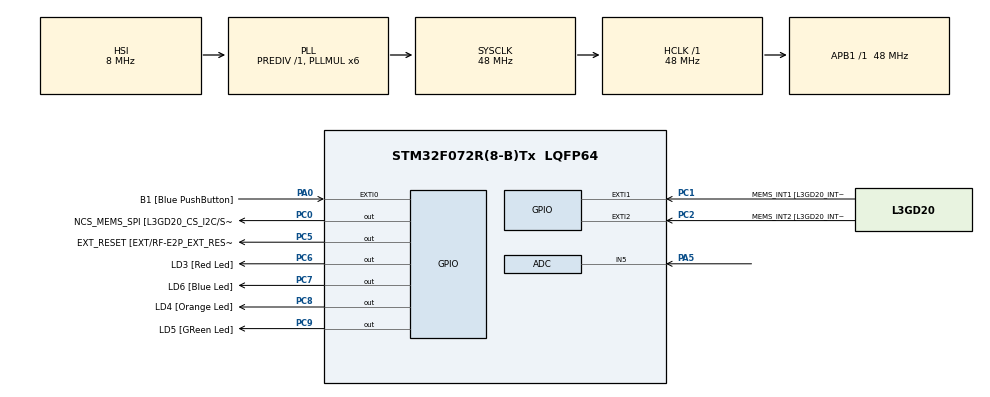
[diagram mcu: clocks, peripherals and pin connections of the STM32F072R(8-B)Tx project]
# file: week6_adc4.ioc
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ADC.ContinuousConvMode=ENABLE
ADC.SamplingTime=ADC_SAMPLETIME_55CYCLES_5
Mcu.Family=STM32F0
Mcu.Name=STM32F072R(8-B)Tx
Mcu.Package=LQFP64
NVIC.ADC1_COMP_IRQn=true\:0\:0\:false\:false\:true\:true\:true\:true
PA0.GPIO_Label=B1 [Blue PushButton]
PA0.GPIO_ModeDefaultEXTI=GPIO_MODE_EVT_RISING
PA0.Signal=GPXTI0
PA11.GPIO_Label=USBF4_DM
PA11.Signal=USB_DM
PA12.GPIO_Label=USBF4_DP
PA12.Signal=USB_DP
PA13.GPIO_Label=SWDIO
PA13.Mode=Serial_Wire
PA13.Signal=SYS_SWDIO
PA14.GPIO_Label=SWCLK
PA14.Mode=Serial_Wire
PA14.Signal=SYS_SWCLK
PA2.Signal=TSC_G1_IO3
PA3.Signal=TSC_G1_IO4
PA5.Mode=IN5
PA5.Signal=ADC_IN5
PA6.Signal=TSC_G2_IO3
PA7.Signal=TSC_G2_IO4
PB0.Signal=TSC_G3_IO2
PB1.Signal=TSC_G3_IO3
PB10.GPIO_Label=I2C2_SCL[EXT/RF-E2P_SCL]
PB10.Signal=I2C2_SCL
PB11.GPIO_Label=I2C2_SDA[EXT/RF-E2P_SDA]
PB11.Signal=I2C2_SDA
PB13.GPIO_Label=SPI2_SCK [L3GD20_SCL/SPC]
PB13.Signal=SPI2_SCK
PB14.GPIO_Label=SPI2_MISO [L3GD20_SDO]
PB14.Signal=SPI2_MISO
PB15.GPIO_Label=SPI2_MOSI [L3GD20_SDA/SDI]
PB15.Signal=SPI2_MOSI
PC0.GPIO_Label=NCS_MEMS_SPI [L3GD20_CS_I2C/SPI]
PC0.Signal=GPIO_Output
PC1.GPIO_Label=MEMS_INT1 [L3GD20_INT1]
PC1.GPIO_ModeDefaultEXTI=GPIO_MODE_EVT_RISING
PC1.Signal=GPXTI1
PC2.GPIO_Label=MEMS_INT2 [L3GD20_INT2]
PC2.GPIO_ModeDefaultEXTI=GPIO_MODE_EVT_RISING
PC2.Signal=GPXTI2
PC5.GPIO_Label=EXT_RESET [EXT/RF-E2P_EXT_RESET]
PC5.Signal=GPIO_Output
PC6.GPIO_Label=LD3 [Red Led]
PC6.Signal=GPIO_Output
PC7.GPIO_Label=LD6 [Blue Led]
PC7.Signal=GPIO_Output
PC8.GPIO_Label=LD4 [Orange Led]
PC8.Signal=GPIO_Output
PC9.GPIO_Label=LD5 [GReen Led]
PC9.Signal=GPIO_Output
ProjectManager.HeapSize=0x200
ProjectManager.StackSize=0x400
ProjectManager.TargetToolchain=STM32CubeIDE
RCC.AHBFreq_Value=48000000
RCC.APB1Freq_Value=48000000
RCC.APB1TimFreq_Value=48000000
RCC.HCLKFreq_Value=48000000
RCC.PLLMUL=RCC_PLL_MUL6
RCC.SYSCLKFreq_VALUE=48000000
RCC.SYSCLKSource=RCC_SYSCLKSOURCE_PLLCLK
board=STM32F072B-DISCO

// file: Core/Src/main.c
/* USER CODE BEGIN Header */
/**
  ******************************************************************************
  * @file           : main.c
  * @brief          : Main program body
  ******************************************************************************
  * @attention
  *
  * Copyright (c) 2024 STMicroelectronics.
  * All rights reserved.
  *
  * This software is licensed under terms that can be found in the LICENSE file
  * in the root directory of this software component.
  * If no LICENSE file comes with this software, it is provided AS-IS.
  *
  ******************************************************************************
  */
/* USER CODE END Header */
#include "main.h"

ADC_HandleTypeDef hadc;
uint16_t adcvalue=0;

void SystemClock_Config(void);
static void MX_GPIO_Init(void);
static void MX_ADC_Init(void);

int main(void)
{

  /* MCU Configuration--------------------------------------------------------*/

  /* Reset of all peripherals, Initializes the Flash interface and the Systick. */
  HAL_Init();

  /* Configure the system clock */
  SystemClock_Config();

  /* Initialize all configured peripherals */
  MX_GPIO_Init();
  MX_ADC_Init();
  /* USER CODE BEGIN 2 */
// Optionally, in case of usage of ADC with interruptions:
//         (++) Configure the NVIC for ADC
//              using function HAL_NVIC_EnableIRQ(ADCx_IRQn)
//         (++) Insert the ADC interruption handler function HAL_ADC_IRQHandler()
//              into the function of corresponding ADC interruption vector
//              ADCx_IRQHandler().
  /* USER CODE END 2 */
HAL_ADC_Start_IT(&hadc);

  /* Infinite loop */
  while (1)
  {

  }
}

void SystemClock_Config(void)
{
  RCC_OscInitTypeDef RCC_OscInitStruct = {0};
  RCC_ClkInitTypeDef RCC_ClkInitStruct = {0};

  /** Initializes the RCC Oscillators according to the specified parameters
  * in the RCC_OscInitTypeDef structure.
  */
  RCC_OscInitStruct.OscillatorType = RCC_OSCILLATORTYPE_HSI|RCC_OSCILLATORTYPE_HSI14;
  RCC_OscInitStruct.HSIState = RCC_HSI_ON;
  RCC_OscInitStruct.HSI14State = RCC_HSI14_ON;
  RCC_OscInitStruct.HSICalibrationValue = RCC_HSICALIBRATION_DEFAULT;
  RCC_OscInitStruct.HSI14CalibrationValue = 16;
  RCC_OscInitStruct.PLL.PLLState = RCC_PLL_ON;
  RCC_OscInitStruct.PLL.PLLSource = RCC_PLLSOURCE_HSI;
  RCC_OscInitStruct.PLL.PLLMUL = RCC_PLL_MUL6;
  RCC_OscInitStruct.PLL.PREDIV = RCC_PREDIV_DIV1;
  if (HAL_RCC_OscConfig(&RCC_OscInitStruct) != HAL_OK)
  {
    Error_Handler();
  }

  /** Initializes the CPU, AHB and APB buses clocks
  */
  RCC_ClkInitStruct.ClockType = RCC_CLOCKTYPE_HCLK|RCC_CLOCKTYPE_SYSCLK
                              |RCC_CLOCKTYPE_PCLK1;
  RCC_ClkInitStruct.SYSCLKSource = RCC_SYSCLKSOURCE_PLLCLK;
  RCC_ClkInitStruct.AHBCLKDivider = RCC_SYSCLK_DIV1;
  RCC_ClkInitStruct.APB1CLKDivider = RCC_HCLK_DIV1;

  if (HAL_RCC_ClockConfig(&RCC_ClkInitStruct, FLASH_LATENCY_1) != HAL_OK)
  {
    Error_Handler();
  }
}

static void MX_ADC_Init(void)
{

  ADC_ChannelConfTypeDef sConfig = {0};

  /** Configure the global features of the ADC (Clock, Resolution, Data Alignment and number of conversion)
  */
  hadc.Instance = ADC1;
  hadc.Init.ClockPrescaler = ADC_CLOCK_ASYNC_DIV1;
  hadc.Init.Resolution = ADC_RESOLUTION_12B;
  hadc.Init.DataAlign = ADC_DATAALIGN_RIGHT;
  hadc.Init.ScanConvMode = ADC_SCAN_DIRECTION_FORWARD;
  hadc.Init.EOCSelection = ADC_EOC_SINGLE_CONV;
  hadc.Init.LowPowerAutoWait = DISABLE;
  hadc.Init.LowPowerAutoPowerOff = DISABLE;
  hadc.Init.ContinuousConvMode = ENABLE;
  hadc.Init.DiscontinuousConvMode = DISABLE;
  hadc.Init.ExternalTrigConv = ADC_SOFTWARE_START;
  hadc.Init.ExternalTrigConvEdge = ADC_EXTERNALTRIGCONVEDGE_NONE;
  hadc.Init.DMAContinuousRequests = DISABLE;
  hadc.Init.Overrun = ADC_OVR_DATA_PRESERVED;
  if (HAL_ADC_Init(&hadc) != HAL_OK)
  {
    Error_Handler();
  }

  /** Configure for the selected ADC regular channel to be converted.
  */
  sConfig.Channel = ADC_CHANNEL_5;
  sConfig.Rank = ADC_RANK_CHANNEL_NUMBER;
  sConfig.SamplingTime = ADC_SAMPLETIME_55CYCLES_5;
  if (HAL_ADC_ConfigChannel(&hadc, &sConfig) != HAL_OK)
  {
    Error_Handler();
  }

}

static void MX_GPIO_Init(void)
{
  GPIO_InitTypeDef GPIO_InitStruct = {0};

  /* GPIO Ports Clock Enable */
  __HAL_RCC_GPIOC_CLK_ENABLE();
  __HAL_RCC_GPIOA_CLK_ENABLE();
  __HAL_RCC_GPIOB_CLK_ENABLE();

  /*Configure GPIO pin Output Level */
  HAL_GPIO_WritePin(GPIOC, NCS_MEMS_SPI_Pin|EXT_RESET_Pin|LD3_Pin|LD6_Pin
                          |LD4_Pin|LD5_Pin, GPIO_PIN_RESET);

  /*Configure GPIO pins : NCS_MEMS_SPI_Pin EXT_RESET_Pin LD3_Pin LD6_Pin
                           LD4_Pin LD5_Pin */
  GPIO_InitStruct.Pin = NCS_MEMS_SPI_Pin|EXT_RESET_Pin|LD3_Pin|LD6_Pin
                          |LD4_Pin|LD5_Pin;
  GPIO_InitStruct.Mode = GPIO_MODE_OUTPUT_PP;
  GPIO_InitStruct.Pull = GPIO_NOPULL;
  GPIO_InitStruct.Speed = GPIO_SPEED_FREQ_LOW;
  HAL_GPIO_Init(GPIOC, &GPIO_InitStruct);

  /*Configure GPIO pins : MEMS_INT1_Pin MEMS_INT2_Pin */
  GPIO_InitStruct.Pin = MEMS_INT1_Pin|MEMS_INT2_Pin;
  GPIO_InitStruct.Mode = GPIO_MODE_EVT_RISING;
  GPIO_InitStruct.Pull = GPIO_NOPULL;
  HAL_GPIO_Init(GPIOC, &GPIO_InitStruct);

  /*Configure GPIO pin : B1_Pin */
  GPIO_InitStruct.Pin = B1_Pin;
  GPIO_InitStruct.Mode = GPIO_MODE_EVT_RISING;
  GPIO_InitStruct.Pull = GPIO_NOPULL;
  HAL_GPIO_Init(B1_GPIO_Port, &GPIO_InitStruct);

  /*Configure GPIO pins : PA2 PA3 PA6 PA7 */
  GPIO_InitStruct.Pin = GPIO_PIN_2|GPIO_PIN_3|GPIO_PIN_6|GPIO_PIN_7;
  GPIO_InitStruct.Mode = GPIO_MODE_AF_PP;
  GPIO_InitStruct.Pull = GPIO_NOPULL;
  GPIO_InitStruct.Speed = GPIO_SPEED_FREQ_LOW;
  GPIO_InitStruct.Alternate = GPIO_AF3_TSC;
  HAL_GPIO_Init(GPIOA, &GPIO_InitStruct);

  /*Configure GPIO pins : PB0 PB1 */
  GPIO_InitStruct.Pin = GPIO_PIN_0|GPIO_PIN_1;
  GPIO_InitStruct.Mode = GPIO_MODE_AF_PP;
  GPIO_InitStruct.Pull = GPIO_NOPULL;
  GPIO_InitStruct.Speed = GPIO_SPEED_FREQ_LOW;
  GPIO_InitStruct.Alternate = GPIO_AF3_TSC;
  HAL_GPIO_Init(GPIOB, &GPIO_InitStruct);

  /*Configure GPIO pins : I2C2_SCL_Pin I2C2_SDA_Pin */
  GPIO_InitStruct.Pin = I2C2_SCL_Pin|I2C2_SDA_Pin;
  GPIO_InitStruct.Mode = GPIO_MODE_AF_OD;
  GPIO_InitStruct.Pull = GPIO_NOPULL;
  GPIO_InitStruct.Speed = GPIO_SPEED_FREQ_HIGH;
  GPIO_InitStruct.Alternate = GPIO_AF1_I2C2;
  HAL_GPIO_Init(GPIOB, &GPIO_InitStruct);

  /*Configure GPIO pins : SPI2_SCK_Pin SPI2_MISO_Pin SPI2_MOSI_Pin */
  GPIO_InitStruct.Pin = SPI2_SCK_Pin|SPI2_MISO_Pin|SPI2_MOSI_Pin;
  GPIO_InitStruct.Mode = GPIO_MODE_AF_PP;
  GPIO_InitStruct.Pull = GPIO_NOPULL;
  GPIO_InitStruct.Speed = GPIO_SPEED_FREQ_HIGH;
  GPIO_InitStruct.Alternate = GPIO_AF0_SPI2;
  HAL_GPIO_Init(GPIOB, &GPIO_InitStruct);

}

void Error_Handler(void)
{
  __disable_irq();
  while (1)
  {
  }
}
